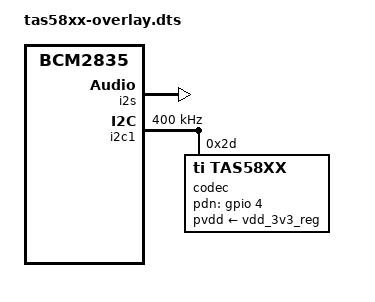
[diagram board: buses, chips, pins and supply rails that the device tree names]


/dts-v1/;
/plugin/;

/ {
    compatible = "brcm,bcm2835";

    fragment@0 {
        target = <&i2s>;
        __overlay__ {
            status = "okay";
        };
    };

    fragment@1 {
        target = <&i2c1>;
        __overlay__ {
            status = "okay";
            clock-frequency = <400000>;
            #address-cells = <1>;
            #size-cells = <0>;

            codec: tas58xx@reg {
                #sound-dai-cells = <0>;
                compatible = "ti,tas58xx";
                reg = <0x2d>;

                pvdd-supply = <&vdd_3v3_reg>;
                pdn-gpios = <&gpio 4 0>;

                ti,modulation-mode = <0>;

                ti,switching-freq = <0>;

                ti,eq-mode = <1>;

                ti,mixer-mode = <0>;

                ti,fault-monitor;
            };
        };
    };

    fragment@2 {
        target = <&sound>;
        __overlay__ {
            status = "okay";
            compatible = "simple-audio-card";
            label = "Louder-Raspberry";
            simple-audio-card,dai-link {

                format = "i2s";
                bitclock-master = <&dailink_master>;
                frame-master = <&dailink_master>;
                dailink_master: cpu {
                        sound-dai = <&i2s>;
                        dai-tdm-slot-num = <2>;
                        dai-tdm-slot-width = <32>;
                };
            codec {
                    sound-dai = <&codec>;
            };
        };
    };

  };
    __overrides__ {
            firmware = <&codec>,"ti,dsp-config-name";
            i2creg = <&codec>,"reg:<>";
            pdn_gpio = <&codec>,"pdn-gpios:4";
            eq_mode = <&codec>,"ti,eq-mode:0";
            mixer_mode = <&codec>,"ti,mixer-mode:0";
            bridge_mode = <&codec>,"ti,bridge-mode?";
            fault_monitor = <&codec>,"ti,fault-monitor?";
    };
};
